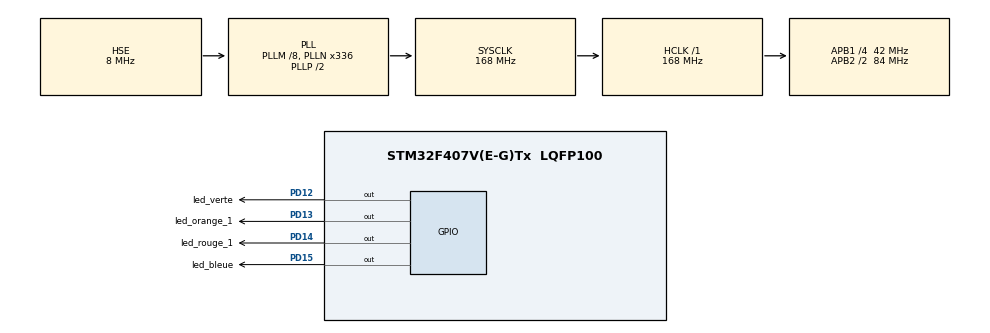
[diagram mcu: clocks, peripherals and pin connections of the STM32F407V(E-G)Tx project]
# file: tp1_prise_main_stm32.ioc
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Mcu.Family=STM32F4
Mcu.Name=STM32F407V(E-G)Tx
Mcu.Package=LQFP100
NVIC.PriorityGroup=NVIC_PRIORITYGROUP_0
PA13.Mode=Serial_Wire
PA13.Signal=SYS_JTMS-SWDIO
PA14.Mode=Serial_Wire
PA14.Signal=SYS_JTCK-SWCLK
PD12.GPIO_Label=led_verte
PD12.GPIO_ModeDefaultOutputPP=GPIO_MODE_OUTPUT_PP
PD12.GPIO_Speed=GPIO_SPEED_FREQ_HIGH
PD12.PinState=GPIO_PIN_RESET
PD12.Signal=GPIO_Output
PD13.GPIO_Label=led_orange_1
PD13.GPIO_Speed=GPIO_SPEED_FREQ_HIGH
PD13.Signal=GPIO_Output
PD14.GPIO_Label=led_rouge_1
PD14.GPIO_Speed=GPIO_SPEED_FREQ_HIGH
PD14.Signal=GPIO_Output
PD15.GPIO_Label=led_bleue
PD15.GPIO_Speed=GPIO_SPEED_FREQ_HIGH
PD15.Signal=GPIO_Output
PH0-OSC_IN.Mode=HSE-External-Oscillator
PH0-OSC_IN.Signal=RCC_OSC_IN
PH1-OSC_OUT.Mode=HSE-External-Oscillator
PH1-OSC_OUT.Signal=RCC_OSC_OUT
ProjectManager.HeapSize=0x200
ProjectManager.StackSize=0x400
ProjectManager.TargetToolchain=STM32CubeIDE
RCC.48MHZClocksFreq_Value=48000000
RCC.AHBFreq_Value=168000000
RCC.APB1CLKDivider=RCC_HCLK_DIV4
RCC.APB1Freq_Value=42000000
RCC.APB1TimFreq_Value=84000000
RCC.APB2CLKDivider=RCC_HCLK_DIV2
RCC.APB2Freq_Value=84000000
RCC.APB2TimFreq_Value=168000000
RCC.CortexFreq_Value=168000000
RCC.HCLKFreq_Value=168000000
RCC.HSE_VALUE=8000000
RCC.HSI_VALUE=16000000
RCC.PLLM=8
RCC.PLLN=336
RCC.PLLQ=7
RCC.PLLSourceVirtual=RCC_PLLSOURCE_HSE
RCC.SYSCLKFreq_VALUE=168000000
RCC.SYSCLKSource=RCC_SYSCLKSOURCE_PLLCLK
RCC.VCOOutputFreq_Value=336000000
board=STM32F407G-DISC1

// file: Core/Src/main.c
/* USER CODE BEGIN Header */
/**
  ******************************************************************************
  * @file           : main.c
  * @brief          : Main program body
  ******************************************************************************
  * @attention
  *
  * Copyright (c) 2024 STMicroelectronics.
  * All rights reserved.
  *
  * This software is licensed under terms that can be found in the LICENSE file
  * in the root directory of this software component.
  * If no LICENSE file comes with this software, it is provided AS-IS.
  *
  ******************************************************************************
  */
/* USER CODE END Header */
#include "main.h"

/* USER CODE BEGIN Includes */
#define ONE_SECOND 1000
/* USER CODE END Includes */
uint16_t factorial(uint16_t n);

/* USER CODE BEGIN PD */
int Delay_time = 250;
int one_second_delay = 1000;

/* USER CODE END PD */

void SystemClock_Config(void);
static void MX_GPIO_Init(void);

int main(void)
{

  /* MCU Configuration--------------------------------------------------------*/

  /* Reset of all peripherals, Initializes the Flash interface and the Systick. */
  HAL_Init();

  /* Configure the system clock */
  SystemClock_Config();

  /* Initialize all configured peripherals */
  MX_GPIO_Init();
  /* USER CODE BEGIN 2 */
  // variables :
  GPIO_TypeDef* green_led = GPIOD;
  GPIO_TypeDef* portA = GPIOA;
  int pins_num = 4;
  int pins[] = {GPIO_PIN_12, GPIO_PIN_13, GPIO_PIN_14, GPIO_PIN_15};
  uint8_t pin_toggle_delay = 1000;
  int pin_speed = 4;

  GPIO_PinState btn_poussoir_state;
  int mavariable = 0;
  btn_poussoir_state = HAL_GPIO_ReadPin(portA, GPIO_PIN_0);

  int toto = 0;

  int tm = 1680000;
  /* USER CODE END 2 */

  /* Infinite loop */
  while (1)
  {
	  //(GPIO_TypeDef*) GPIOD = GPIOD;

	  /*
	  // blink LEDs

	  if (GPIOD->ODR & 0x0000F000) // GPIOD−>ODR & 0x0000F000
	  {
		  GPIOD->BSRR |= 0xF0000000 ;
	  }
	  else
	  {
		  GPIOD->BSRR |= 0x0000F000 ;
	  }
	  HAL_Delay(Delay_time) ;
	  */

	  // Turn on the Green LED
	  /*
	  HAL_GPIO_WritePin(green_led, GPIO_PIN_12, GPIO_PIN_SET);
	  HAL_Delay(1000);
	  // turn it off
	  HAL_GPIO_WritePin(green_led, GPIO_PIN_12, GPIO_PIN_RESET);
	  HAL_Delay(1000);

	  HAL_GPIO_TogglePin(green_led, GPIO_PIN_12);
	  HAL_Delay(1000);

	  // 2

	  int t = 1000;
	  for(int i = 0; i < pins_num; i++)
	  {

		  uint16_t current_pin = ((uint16_t)pins[i]);

		  HAL_GPIO_TogglePin(green_led, current_pin);
	  }
		  HAL_Delay(pin_toggle_delay);

	  // =========== CHENILLARD ==============
	  // 3 bouton poussoir
		  GPIO_PinState btn_poussoir_state;
		  int mavariable = 0;
		  btn_poussoir_state = HAL_GPIO_ReadPin(portA, GPIO_PIN_0);
		  if(btn_poussoir_state == GPIO_PIN_SET){
			  mavariable = 1;
			  pin_toggle_delay /= pin_speed;
		  }
		  else{
			  mavariable = 0;
		  }

	  for(int i = 0; i < pins_num; i++)
	  {

		  uint16_t current_pin = ((uint16_t)pins[i]);

		  HAL_GPIO_TogglePin(green_led, current_pin);
		  HAL_Delay(pin_toggle_delay);
		  HAL_GPIO_TogglePin(green_led, current_pin);
		  HAL_Delay(pin_toggle_delay);
	  }

	  // ============== TP2 Programmation en C ==========
	  // 1
	  if(btn_poussoir_state == GPIO_PIN_SET){
		  mavariable = 1;
		  pin_toggle_delay /= pin_speed;
		  HAL_GPIO_WritePin(green_led, GPIO_PIN_14, GPIO_PIN_SET);
	  }
	  // 2
	  if(btn_poussoir_state == GPIO_PIN_SET){
		  mavariable = 1;
		  pin_toggle_delay /= pin_speed;
		  HAL_GPIO_WritePin(green_led, GPIO_PIN_14, GPIO_PIN_SET);
	  }
	  else{
		  mavariable = 0;
		  HAL_GPIO_WritePin(green_led, GPIO_PIN_14, GPIO_PIN_RESET);
	  }

	  // 3
	  btn_poussoir_state = HAL_GPIO_ReadPin(portA, GPIO_PIN_0);
	  switch(toto){

	  case 0:
		  if(btn_poussoir_state == GPIO_PIN_SET){
			  HAL_GPIO_WritePin(green_led, GPIO_PIN_12, GPIO_PIN_SET);
			  HAL_GPIO_WritePin(green_led, GPIO_PIN_14, GPIO_PIN_SET);
		  }
		  else{
			  HAL_GPIO_WritePin(green_led, GPIO_PIN_15, GPIO_PIN_SET);
		  }
		  break;
	  case 1:
		  if(btn_poussoir_state == GPIO_PIN_SET){
			  HAL_GPIO_WritePin(green_led, GPIO_PIN_13, GPIO_PIN_SET);
		  }
		  else{
			  HAL_GPIO_WritePin(green_led, GPIO_PIN_14, GPIO_PIN_SET);
			  HAL_GPIO_WritePin(green_led, GPIO_PIN_13, GPIO_PIN_SET);
		  }
		  break;
	  default:
		  break;
	  }
	  HAL_GPIO_WritePin(green_led, GPIO_PIN_15, GPIO_PIN_RESET);
	  HAL_GPIO_WritePin(green_led, GPIO_PIN_14, GPIO_PIN_RESET);
	  HAL_GPIO_WritePin(green_led, GPIO_PIN_13, GPIO_PIN_RESET);
	  HAL_GPIO_WritePin(green_led, GPIO_PIN_12, GPIO_PIN_RESET);

	  // Tempo
	  uint32_t max_val = 4294967294;
	  uint32_t tempo_var = 0;
	  while(tempo_var < max_val){
		  tempo_var ++;
	  }
	  //while((tempo_var++) < max_val);
	  tempo_var = 0;
	*/
	  HAL_GPIO_TogglePin(green_led, GPIO_PIN_12);
	  custom_delay(tm);
	  int res = factorial(4);
  }
}

// 2
uint16_t factorial(uint16_t n){
	// il faut que n soit choisit de sorte que son factoriel ne soit pas supérieur à 2^32
	uint16_t res = 1;
	for(int i = n; i > 1; i--){
		res = res * i;
		//res *= i;
	}
	return res;
}
// 3
// A revoir !!
void custom_delay(uint32_t max_val){
  uint32_t tempo_var = 0;
  while(tempo_var < max_val){
	  tempo_var ++;
  }
  //while((tempo_var++) < max_val);
  tempo_var = 0;
}

void SystemClock_Config(void)
{
  RCC_OscInitTypeDef RCC_OscInitStruct = {0};
  RCC_ClkInitTypeDef RCC_ClkInitStruct = {0};

  /** Configure the main internal regulator output voltage
  */
  __HAL_RCC_PWR_CLK_ENABLE();
  __HAL_PWR_VOLTAGESCALING_CONFIG(PWR_REGULATOR_VOLTAGE_SCALE1);

  /** Initializes the RCC Oscillators according to the specified parameters
  * in the RCC_OscInitTypeDef structure.
  */
  RCC_OscInitStruct.OscillatorType = RCC_OSCILLATORTYPE_HSE;
  RCC_OscInitStruct.HSEState = RCC_HSE_ON;
  RCC_OscInitStruct.PLL.PLLState = RCC_PLL_ON;
  RCC_OscInitStruct.PLL.PLLSource = RCC_PLLSOURCE_HSE;
  RCC_OscInitStruct.PLL.PLLM = 8;
  RCC_OscInitStruct.PLL.PLLN = 336;
  RCC_OscInitStruct.PLL.PLLP = RCC_PLLP_DIV2;
  RCC_OscInitStruct.PLL.PLLQ = 7;
  if (HAL_RCC_OscConfig(&RCC_OscInitStruct) != HAL_OK)
  {
    Error_Handler();
  }

  /** Initializes the CPU, AHB and APB buses clocks
  */
  RCC_ClkInitStruct.ClockType = RCC_CLOCKTYPE_HCLK|RCC_CLOCKTYPE_SYSCLK
                              |RCC_CLOCKTYPE_PCLK1|RCC_CLOCKTYPE_PCLK2;
  RCC_ClkInitStruct.SYSCLKSource = RCC_SYSCLKSOURCE_PLLCLK;
  RCC_ClkInitStruct.AHBCLKDivider = RCC_SYSCLK_DIV1;
  RCC_ClkInitStruct.APB1CLKDivider = RCC_HCLK_DIV4;
  RCC_ClkInitStruct.APB2CLKDivider = RCC_HCLK_DIV2;

  if (HAL_RCC_ClockConfig(&RCC_ClkInitStruct, FLASH_LATENCY_5) != HAL_OK)
  {
    Error_Handler();
  }
}

static void MX_GPIO_Init(void)
{
  GPIO_InitTypeDef GPIO_InitStruct = {0};

  /* GPIO Ports Clock Enable */
  __HAL_RCC_GPIOH_CLK_ENABLE();
  __HAL_RCC_GPIOD_CLK_ENABLE();
  __HAL_RCC_GPIOA_CLK_ENABLE();

  /*Configure GPIO pin Output Level */
  HAL_GPIO_WritePin(GPIOD, led_verte_Pin|led_orange_1_Pin|led_rouge_1_Pin|led_bleue_Pin, GPIO_PIN_RESET);

  /*Configure GPIO pins : led_verte_Pin led_orange_1_Pin led_rouge_1_Pin led_bleue_Pin */
  GPIO_InitStruct.Pin = led_verte_Pin|led_orange_1_Pin|led_rouge_1_Pin|led_bleue_Pin;
  GPIO_InitStruct.Mode = GPIO_MODE_OUTPUT_PP;
  GPIO_InitStruct.Pull = GPIO_NOPULL;
  GPIO_InitStruct.Speed = GPIO_SPEED_FREQ_HIGH;
  HAL_GPIO_Init(GPIOD, &GPIO_InitStruct);

}

void Error_Handler(void)
{
  __disable_irq();
  while (1)
  {
  }
}
